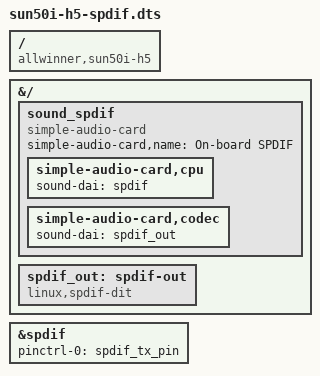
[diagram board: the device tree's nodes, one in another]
//SPDX-License-Identifier: GPL-2.0+ or MIT
//Copyright (C) 2021-present Team LibreELEC (https://libreelec.tv)
/dts-v1/;
/plugin/;

/ {
	compatible = "allwinner,sun50i-h5";
};

&{/} {
	sound_spdif {
		compatible = "simple-audio-card";
		simple-audio-card,name = "On-board SPDIF";

		simple-audio-card,cpu {
			sound-dai = <&spdif>;
		};

		simple-audio-card,codec {
			sound-dai = <&spdif_out>;
		};
	};

	spdif_out: spdif-out {
		#sound-dai-cells = <0>;
		compatible = "linux,spdif-dit";
	};
};

&spdif {
	pinctrl-names = "default";
	pinctrl-0 = <&spdif_tx_pin>;
	status = "okay";
};
